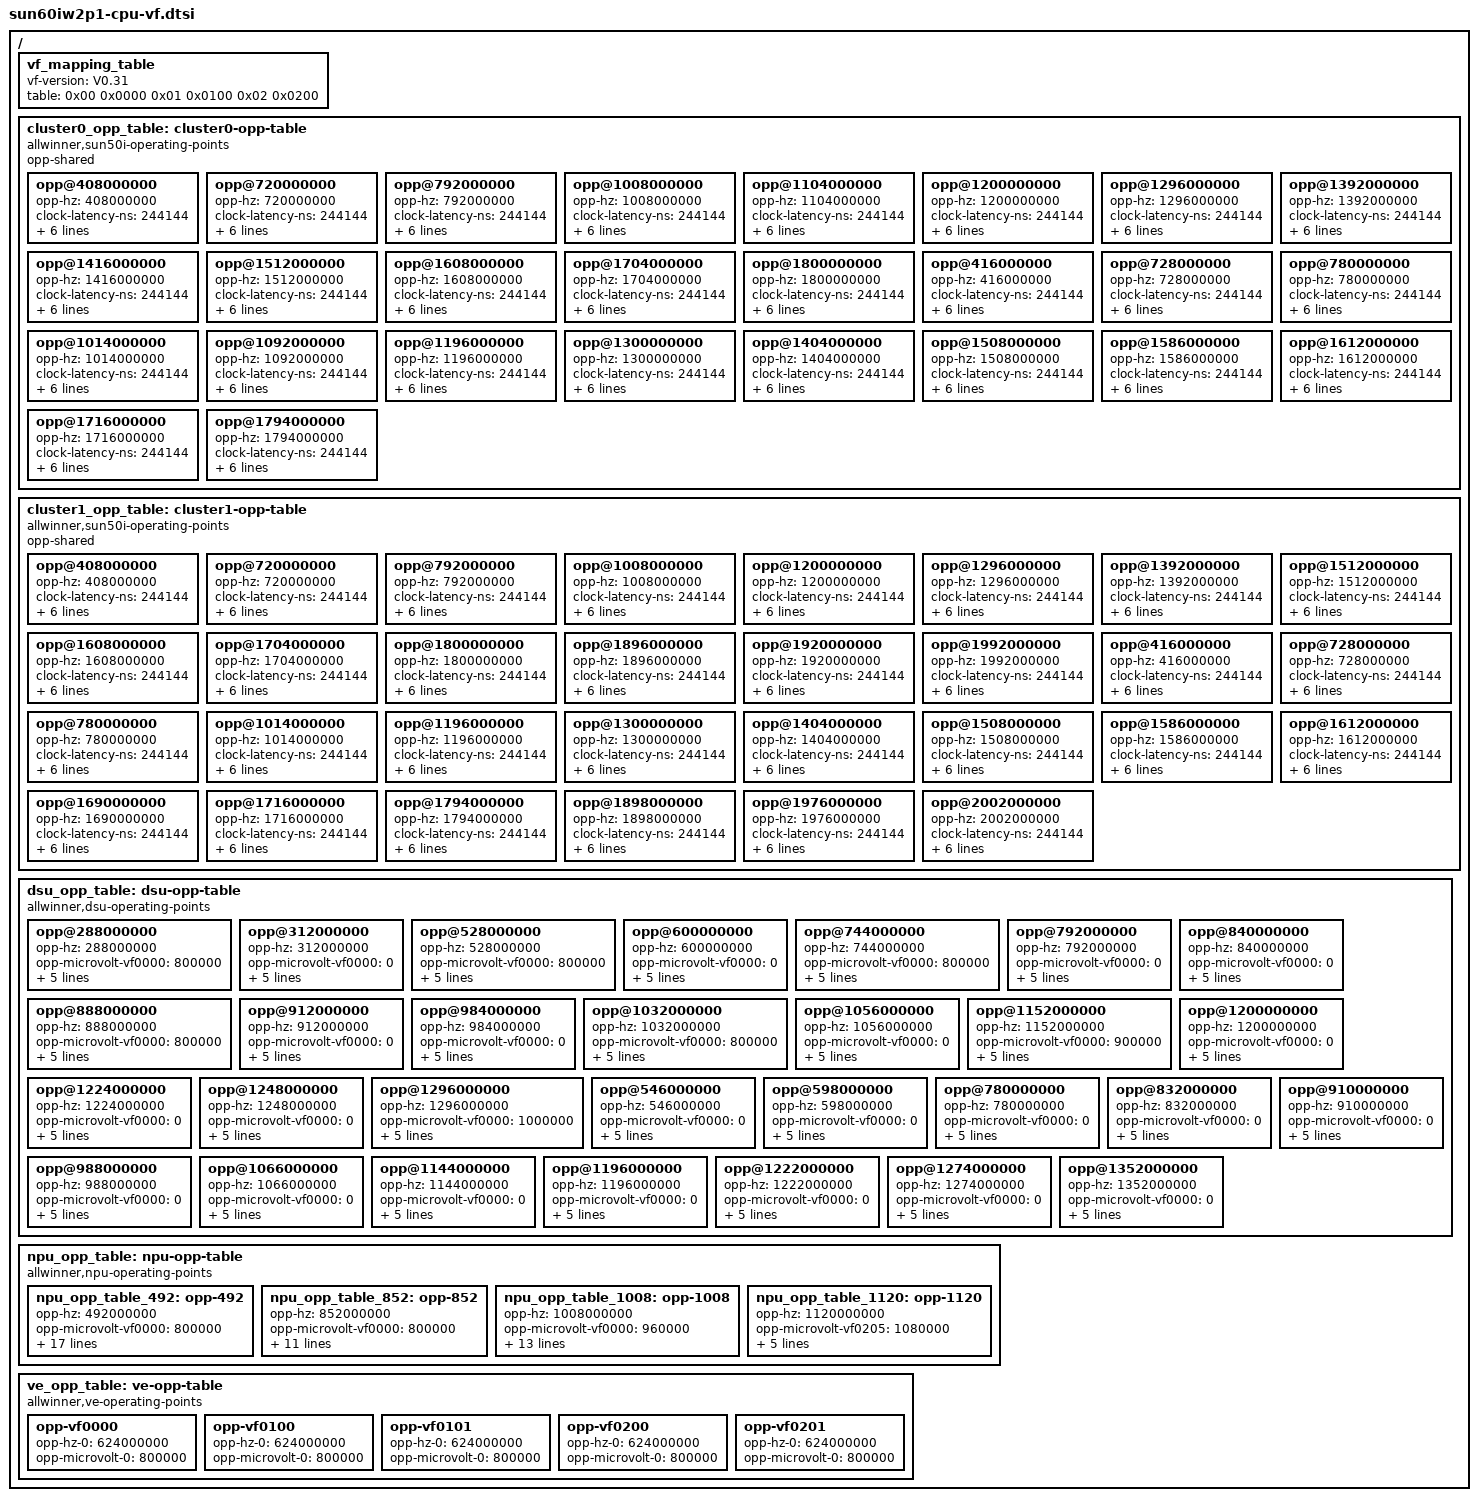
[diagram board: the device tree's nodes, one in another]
/* SPDX-License-Identifier: GPL-2.0-or-later */
/{
	vf_mapping_table: vf_mapping_table {
		vf-version = "V0.31";
		table = <
			0x00 0x0000
			0x01 0x0100
			0x02 0x0200
			>;
	};

	cluster0_opp_table: cluster0-opp-table {
		compatible = "allwinner,sun50i-operating-points";
		opp-shared;

		opp@408000000 {
			opp-hz = /bits/ 64 <408000000>;
			clock-latency-ns = <244144>; /* 8 32k periods */
			opp-microvolt-vf0000 = <800000>;
			opp-microvolt-vf0100 = <800000>;
			opp-microvolt-vf0200 = <800000>;
			opp-microvolt-26m-vf0000 = <0>;
			opp-microvolt-26m-vf0100 = <0>;
			opp-microvolt-26m-vf0200 = <0>;
		};

		opp@720000000 {
			opp-hz = /bits/ 64 <720000000>;
			clock-latency-ns = <244144>; /* 8 32k periods */
			opp-microvolt-vf0000 = <800000>;
			opp-microvolt-vf0100 = <0>;
			opp-microvolt-vf0200 = <0>;
			opp-microvolt-26m-vf0000 = <0>;
			opp-microvolt-26m-vf0100 = <0>;
			opp-microvolt-26m-vf0200 = <0>;
		};

		opp@792000000 {
			opp-hz = /bits/ 64 <792000000>;
			clock-latency-ns = <244144>; /* 8 32k periods */
			opp-microvolt-vf0000 = <0>;
			opp-microvolt-vf0100 = <800000>;
			opp-microvolt-vf0200 = <800000>;
			opp-microvolt-26m-vf0000 = <0>;
			opp-microvolt-26m-vf0100 = <0>;
			opp-microvolt-26m-vf0200 = <0>;
		};

		opp@1008000000 {
			opp-hz = /bits/ 64 <1008000000>;
			clock-latency-ns = <244144>; /* 8 32k periods */
			opp-microvolt-vf0000 = <800000>;
			opp-microvolt-vf0100 = <800000>;
			opp-microvolt-vf0200 = <800000>;
			opp-microvolt-26m-vf0000 = <0>;
			opp-microvolt-26m-vf0100 = <0>;
			opp-microvolt-26m-vf0200 = <0>;
		};

		opp@1104000000 {
			opp-hz = /bits/ 64 <1104000000>;
			clock-latency-ns = <244144>; /* 8 32k periods */
			opp-microvolt-vf0000 = <0>;
			opp-microvolt-vf0100 = <800000>;
			opp-microvolt-vf0200 = <0>;
			opp-microvolt-26m-vf0000 = <0>;
			opp-microvolt-26m-vf0100 = <0>;
			opp-microvolt-26m-vf0200 = <0>;
		};


		opp@1200000000 {
			opp-hz = /bits/ 64 <1200000000>;
			clock-latency-ns = <244144>; /* 8 32k periods */
			opp-microvolt-vf0000 = <800000>;
			opp-microvolt-vf0100 = <850000>;
			opp-microvolt-vf0200 = <800000>;
			opp-microvolt-26m-vf0000 = <0>;
			opp-microvolt-26m-vf0100 = <0>;
			opp-microvolt-26m-vf0200 = <0>;
		};

		opp@1296000000 {
			opp-hz = /bits/ 64 <1296000000>;
			clock-latency-ns = <244144>; /* 8 32k periods */
			opp-microvolt-vf0000 = <0>;
			opp-microvolt-vf0100 = <900000>;
			opp-microvolt-vf0200 = <800000>;
			opp-microvolt-26m-vf0000 = <0>;
			opp-microvolt-26m-vf0100 = <0>;
			opp-microvolt-26m-vf0200 = <0>;
		};


		opp@1392000000 {
			opp-hz = /bits/ 64 <1392000000>;
			clock-latency-ns = <244144>; /* 8 32k periods */
			opp-microvolt-vf0000 = <0>;
			opp-microvolt-vf0100 = <950000>;
			opp-microvolt-vf0200 = <850000>;
			opp-microvolt-26m-vf0000 = <0>;
			opp-microvolt-26m-vf0100 = <0>;
			opp-microvolt-26m-vf0200 = <0>;
		};

		opp@1416000000 {
			opp-hz = /bits/ 64 <1416000000>;
			clock-latency-ns = <244144>; /* 8 32k periods */
			opp-microvolt-vf0000 = <800000>;
			opp-microvolt-vf0100 = <0>;
			opp-microvolt-vf0200 = <0>;
			opp-microvolt-26m-vf0000 = <0>;
			opp-microvolt-26m-vf0100 = <0>;
			opp-microvolt-26m-vf0200 = <0>;
		};

		opp@1512000000 {
			opp-hz = /bits/ 64 <1512000000>;
			clock-latency-ns = <244144>; /* 8 32k periods */
			opp-microvolt-vf0000 = <0>;
			opp-microvolt-vf0100 = <1000000>;
			opp-microvolt-vf0200 = <900000>;
			opp-microvolt-26m-vf0000 = <0>;
			opp-microvolt-26m-vf0100 = <0>;
			opp-microvolt-26m-vf0200 = <0>;
		};

		opp@1608000000 {
			opp-hz = /bits/ 64 <1608000000>;
			clock-latency-ns = <244144>; /* 8 32k periods */
			opp-microvolt-vf0000 = <900000>;
			opp-microvolt-vf0100 = <1050000>;
			opp-microvolt-vf0200 = <950000>;
			opp-microvolt-26m-vf0000 = <0>;
			opp-microvolt-26m-vf0100 = <0>;
			opp-microvolt-26m-vf0200 = <0>;
		};

		opp@1704000000 {
			opp-hz = /bits/ 64 <1704000000>;
			clock-latency-ns = <244144>; /* 8 32k periods */
			opp-microvolt-vf0000 = <0>;
			opp-microvolt-vf0100 = <0>;
			opp-microvolt-vf0200 = <1000000>;
			opp-microvolt-26m-vf0000 = <0>;
			opp-microvolt-26m-vf0100 = <0>;
			opp-microvolt-26m-vf0200 = <0>;
		};

		opp@1800000000 {
			opp-hz = /bits/ 64 <1800000000>;
			clock-latency-ns = <244144>; /* 8 32k periods */
			opp-microvolt-vf0000 = <1000000>;
			opp-microvolt-vf0100 = <0>;
			opp-microvolt-vf0200 = <1050000>;
			opp-microvolt-26m-vf0000 = <0>;
			opp-microvolt-26m-vf0100 = <0>;
			opp-microvolt-26m-vf0200 = <0>;
		};

		/* support 26m clock source */
		opp@416000000 {
			opp-hz = /bits/ 64 <416000000>;
			clock-latency-ns = <244144>;
			opp-microvolt-vf0000 = <0>;
			opp-microvolt-vf0100 = <0>;
			opp-microvolt-vf0200 = <0>;
			opp-microvolt-26m-vf0000 = <800000>;
			opp-microvolt-26m-vf0100 = <800000>;
			opp-microvolt-26m-vf0200 = <800000>;
		};

		opp@728000000 {
			opp-hz = /bits/ 64 <728000000>;
			clock-latency-ns = <244144>;
			opp-microvolt-vf0000 = <0>;
			opp-microvolt-vf0100 = <0>;
			opp-microvolt-vf0200 = <0>;
			opp-microvolt-26m-vf0000 = <800000>;
			opp-microvolt-26m-vf0100 = <0>;
			opp-microvolt-26m-vf0200 = <0>;
		};

		opp@780000000 {
			opp-hz = /bits/ 64 <780000000>;
			clock-latency-ns = <244144>;
			opp-microvolt-vf0000 = <0>;
			opp-microvolt-vf0100 = <0>;
			opp-microvolt-vf0200 = <0>;
			opp-microvolt-26m-vf0000 = <0>;
			opp-microvolt-26m-vf0100 = <800000>;
			opp-microvolt-26m-vf0200 = <800000>;
		};

		opp@1014000000 {
			opp-hz = /bits/ 64 <1014000000>;
			clock-latency-ns = <244144>;
			opp-microvolt-vf0000 = <0>;
			opp-microvolt-vf0100 = <0>;
			opp-microvolt-vf0200 = <0>;
			opp-microvolt-26m-vf0000 = <800000>;
			opp-microvolt-26m-vf0100 = <800000>;
			opp-microvolt-26m-vf0200 = <800000>;
		};

		opp@1092000000 {
			opp-hz = /bits/ 64 <1092000000>;
			clock-latency-ns = <244144>;
			opp-microvolt-vf0000 = <0>;
			opp-microvolt-vf0100 = <0>;
			opp-microvolt-vf0200 = <0>;
			opp-microvolt-26m-vf0000 = <0>;
			opp-microvolt-26m-vf0100 = <800000>;
			opp-microvolt-26m-vf0200 = <0>;
		};

		opp@1196000000 {
			opp-hz = /bits/ 64 <1196000000>;
			clock-latency-ns = <244144>;
			opp-microvolt-vf0000 = <0>;
			opp-microvolt-vf0100 = <0>;
			opp-microvolt-vf0200 = <0>;
			opp-microvolt-26m-vf0000 = <800000>;
			opp-microvolt-26m-vf0100 = <850000>;
			opp-microvolt-26m-vf0200 = <800000>;
		};

		opp@1300000000 {
			opp-hz = /bits/ 64 <1300000000>;
			clock-latency-ns = <244144>;
			opp-microvolt-vf0000 = <0>;
			opp-microvolt-vf0100 = <0>;
			opp-microvolt-vf0200 = <0>;
			opp-microvolt-26m-vf0000 = <0>;
			opp-microvolt-26m-vf0100 = <900000>;
			opp-microvolt-26m-vf0200 = <800000>;
		};

		opp@1404000000 {
			opp-hz = /bits/ 64 <1404000000>;
			clock-latency-ns = <244144>;
			opp-microvolt-vf0000 = <0>;
			opp-microvolt-vf0100 = <0>;
			opp-microvolt-vf0200 = <0>;
			opp-microvolt-26m-vf0000 = <800000>;
			opp-microvolt-26m-vf0100 = <950000>;
			opp-microvolt-26m-vf0200 = <850000>;
		};

		opp@1508000000 {
			opp-hz = /bits/ 64 <1508000000>;
			clock-latency-ns = <244144>;
			opp-microvolt-vf0000 = <0>;
			opp-microvolt-vf0100 = <0>;
			opp-microvolt-vf0200 = <0>;
			opp-microvolt-26m-vf0000 = <0>;
			opp-microvolt-26m-vf0100 = <1000000>;
			opp-microvolt-26m-vf0200 = <900000>;
		};

		opp@1586000000 {
			opp-hz = /bits/ 64 <1586000000>;
			clock-latency-ns = <244144>;
			opp-microvolt-vf0000 = <0>;
			opp-microvolt-vf0100 = <0>;
			opp-microvolt-vf0200 = <0>;
			opp-microvolt-26m-vf0000 = <900000>;
			opp-microvolt-26m-vf0100 = <0>;
			opp-microvolt-26m-vf0200 = <0>;
		};

		opp@1612000000 {
			opp-hz = /bits/ 64 <1612000000>;
			clock-latency-ns = <244144>;
			opp-microvolt-vf0000 = <0>;
			opp-microvolt-vf0100 = <0>;
			opp-microvolt-vf0200 = <0>;
			opp-microvolt-26m-vf0000 = <0>;
			opp-microvolt-26m-vf0100 = <1050000>;
			opp-microvolt-26m-vf0200 = <950000>;
		};

		opp@1716000000 {
			opp-hz = /bits/ 64 <1716000000>;
			clock-latency-ns = <244144>;
			opp-microvolt-vf0000 = <0>;
			opp-microvolt-vf0100 = <0>;
			opp-microvolt-vf0200 = <0>;
			opp-microvolt-26m-vf0000 = <0>;
			opp-microvolt-26m-vf0100 = <0>;
			opp-microvolt-26m-vf0200 = <1000000>;
		};

		opp@1794000000 {
			opp-hz = /bits/ 64 <1794000000>;
			clock-latency-ns = <244144>;
			opp-microvolt-vf0000 = <0>;
			opp-microvolt-vf0100 = <0>;
			opp-microvolt-vf0200 = <0>;
			opp-microvolt-26m-vf0000 = <1000000>;
			opp-microvolt-26m-vf0100 = <0>;
			opp-microvolt-26m-vf0200 = <1050000>;
		};
	};

	cluster1_opp_table: cluster1-opp-table {
		compatible = "allwinner,sun50i-operating-points";
		opp-shared;

		opp@408000000 {
			opp-hz = /bits/ 64 <408000000>;
			clock-latency-ns = <244144>; /* 8 32k periods */
			opp-microvolt-vf0000 = <800000>;
			opp-microvolt-vf0100 = <800000>;
			opp-microvolt-vf0200 = <800000>;
			opp-microvolt-26m-vf0000 = <0>;
			opp-microvolt-26m-vf0100 = <0>;
			opp-microvolt-26m-vf0200 = <0>;
		};

		opp@720000000 {
			opp-hz = /bits/ 64 <720000000>;
			clock-latency-ns = <244144>; /* 8 32k periods */
			opp-microvolt-vf0000 = <800000>;
			opp-microvolt-vf0100 = <0>;
			opp-microvolt-vf0200 = <0>;
			opp-microvolt-26m-vf0000 = <0>;
			opp-microvolt-26m-vf0100 = <0>;
			opp-microvolt-26m-vf0200 = <0>;
		};

		opp@792000000 {
			opp-hz = /bits/ 64 <792000000>;
			clock-latency-ns = <244144>; /* 8 32k periods */
			opp-microvolt-vf0000 = <0>;
			opp-microvolt-vf0100 = <800000>;
			opp-microvolt-vf0200 = <800000>;
			opp-microvolt-26m-vf0000 = <0>;
			opp-microvolt-26m-vf0100 = <0>;
			opp-microvolt-26m-vf0200 = <0>;
		};


		opp@1008000000 {
			opp-hz = /bits/ 64 <1008000000>;
			clock-latency-ns = <244144>; /* 8 32k periods */
			opp-microvolt-vf0000 = <800000>;
			opp-microvolt-vf0100 = <800000>;
			opp-microvolt-vf0200 = <800000>;
			opp-microvolt-26m-vf0000 = <0>;
			opp-microvolt-26m-vf0100 = <0>;
			opp-microvolt-26m-vf0200 = <0>;
		};

		opp@1200000000 {
			opp-hz = /bits/ 64 <1200000000>;
			clock-latency-ns = <244144>; /* 8 32k periods */
			opp-microvolt-vf0000 = <800000>;
			opp-microvolt-vf0100 = <800000>;
			opp-microvolt-vf0200 = <800000>;
			opp-microvolt-26m-vf0000 = <0>;
			opp-microvolt-26m-vf0100 = <0>;
			opp-microvolt-26m-vf0200 = <0>;
		};

		opp@1296000000 {
			opp-hz = /bits/ 64 <1296000000>;
			clock-latency-ns = <244144>; /* 8 32k periods */
			opp-microvolt-vf0000 = <0>;
			opp-microvolt-vf0100 = <800000>;
			opp-microvolt-vf0200 = <0>;
			opp-microvolt-26m-vf0000 = <0>;
			opp-microvolt-26m-vf0100 = <0>;
			opp-microvolt-26m-vf0200 = <0>;
		};

		opp@1392000000 {
			opp-hz = /bits/ 64 <1392000000>;
			clock-latency-ns = <244144>; /* 8 32k periods */
			opp-microvolt-vf0000 = <800000>;
			opp-microvolt-vf0100 = <850000>;
			opp-microvolt-vf0200 = <800000>;
			opp-microvolt-26m-vf0000 = <0>;
			opp-microvolt-26m-vf0100 = <0>;
			opp-microvolt-26m-vf0200 = <0>;
		};

		opp@1512000000 {
			opp-hz = /bits/ 64 <1512000000>;
			clock-latency-ns = <244144>; /* 8 32k periods */
			opp-microvolt-vf0000 = <800000>;
			opp-microvolt-vf0100 = <900000>;
			opp-microvolt-vf0200 = <800000>;
			opp-microvolt-26m-vf0000 = <0>;
			opp-microvolt-26m-vf0100 = <0>;
			opp-microvolt-26m-vf0200 = <0>;
		};

		opp@1608000000 {
			opp-hz = /bits/ 64 <1608000000>;
			clock-latency-ns = <244144>; /* 8 32k periods */
			opp-microvolt-vf0000 = <850000>;
			opp-microvolt-vf0100 = <950000>;
			opp-microvolt-vf0200 = <850000>;
			opp-microvolt-26m-vf0000 = <0>;
			opp-microvolt-26m-vf0100 = <0>;
			opp-microvolt-26m-vf0200 = <0>;
		};

		opp@1704000000 {
			opp-hz = /bits/ 64 <1704000000>;
			clock-latency-ns = <244144>; /* 8 32k periods */
			opp-microvolt-vf0000 = <900000>;
			opp-microvolt-vf0100 = <1000000>;
			opp-microvolt-vf0200 = <900000>;
			opp-microvolt-26m-vf0000 = <0>;
			opp-microvolt-26m-vf0100 = <0>;
			opp-microvolt-26m-vf0200 = <0>;
		};

		opp@1800000000 {
			opp-hz = /bits/ 64 <1800000000>;
			clock-latency-ns = <244144>; /* 8 32k periods */
			opp-microvolt-vf0000 = <950000>;
			opp-microvolt-vf0100 = <1050000>;
			opp-microvolt-vf0200 = <950000>;
			opp-microvolt-26m-vf0000 = <0>;
			opp-microvolt-26m-vf0100 = <0>;
			opp-microvolt-26m-vf0200 = <0>;
		};

		opp@1896000000 {
			opp-hz = /bits/ 64 <1896000000>;
			clock-latency-ns = <244144>; /* 8 32k periods */
			opp-microvolt-vf0000 = <0>;
			opp-microvolt-vf0100 = <0>;
			opp-microvolt-vf0200 = <1000000>;
			opp-microvolt-26m-vf0000 = <0>;
			opp-microvolt-26m-vf0100 = <0>;
			opp-microvolt-26m-vf0200 = <0>;
		};


		opp@1920000000 {
			opp-hz = /bits/ 64 <1920000000>;
			clock-latency-ns = <244144>; /* 8 32k periods */
			opp-microvolt-vf0000 = <1000000>;
			opp-microvolt-vf0100 = <0>;
			opp-microvolt-vf0200 = <0>;
			opp-microvolt-26m-vf0000 = <0>;
			opp-microvolt-26m-vf0100 = <0>;
			opp-microvolt-26m-vf0200 = <0>;
		};

		opp@1992000000 {
			opp-hz = /bits/ 64 <1992000000>;
			clock-latency-ns = <244144>; /* 8 32k periods */
			opp-microvolt-vf0000 = <1050000>;
			opp-microvolt-vf0100 = <0>;
			opp-microvolt-vf0200 = <1050000>;
			opp-microvolt-26m-vf0000 = <0>;
			opp-microvolt-26m-vf0100 = <0>;
			opp-microvolt-26m-vf0200 = <0>;
		};


		/* support 26m clock source */
		opp@416000000 {
			opp-hz = /bits/ 64 <416000000>;
			clock-latency-ns = <244144>;
			opp-microvolt-vf0000 = <0>;
			opp-microvolt-vf0100 = <0>;
			opp-microvolt-vf0200 = <0>;
			opp-microvolt-26m-vf0000 = <800000>;
			opp-microvolt-26m-vf0100 = <800000>;
			opp-microvolt-26m-vf0200 = <800000>;
		};

		opp@728000000 {
			opp-hz = /bits/ 64 <728000000>;
			clock-latency-ns = <244144>;
			opp-microvolt-vf0000 = <0>;
			opp-microvolt-vf0100 = <0>;
			opp-microvolt-vf0200 = <0>;
			opp-microvolt-26m-vf0000 = <800000>;
			opp-microvolt-26m-vf0100 = <0>;
			opp-microvolt-26m-vf0200 = <0>;
		};

		opp@780000000 {
			opp-hz = /bits/ 64 <780000000>;
			clock-latency-ns = <244144>;
			opp-microvolt-vf0000 = <0>;
			opp-microvolt-vf0100 = <0>;
			opp-microvolt-vf0200 = <0>;
			opp-microvolt-26m-vf0000 = <0>;
			opp-microvolt-26m-vf0100 = <800000>;
			opp-microvolt-26m-vf0200 = <800000>;
		};

		opp@1014000000 {
			opp-hz = /bits/ 64 <1014000000>;
			clock-latency-ns = <244144>;
			opp-microvolt-vf0000 = <0>;
			opp-microvolt-vf0100 = <0>;
			opp-microvolt-vf0200 = <0>;
			opp-microvolt-26m-vf0000 = <800000>;
			opp-microvolt-26m-vf0100 = <800000>;
			opp-microvolt-26m-vf0200 = <800000>;
		};

		opp@1196000000 {
			opp-hz = /bits/ 64 <1196000000>;
			clock-latency-ns = <244144>;
			opp-microvolt-vf0000 = <0>;
			opp-microvolt-vf0100 = <0>;
			opp-microvolt-vf0200 = <0>;
			opp-microvolt-26m-vf0000 = <800000>;
			opp-microvolt-26m-vf0100 = <800000>;
			opp-microvolt-26m-vf0200 = <800000>;
		};

		opp@1300000000 {
			opp-hz = /bits/ 64 <1300000000>;
			clock-latency-ns = <244144>;
			opp-microvolt-vf0000 = <0>;
			opp-microvolt-vf0100 = <0>;
			opp-microvolt-vf0200 = <0>;
			opp-microvolt-26m-vf0000 = <0>;
			opp-microvolt-26m-vf0100 = <800000>;
			opp-microvolt-26m-vf0200 = <0>;
		};

		opp@1404000000 {
			opp-hz = /bits/ 64 <1404000000>;
			clock-latency-ns = <244144>;
			opp-microvolt-vf0000 = <0>;
			opp-microvolt-vf0100 = <0>;
			opp-microvolt-vf0200 = <0>;
			opp-microvolt-26m-vf0000 = <800000>;
			opp-microvolt-26m-vf0100 = <850000>;
			opp-microvolt-26m-vf0200 = <800000>;
		};

		opp@1508000000 {
			opp-hz = /bits/ 64 <1508000000>;
			clock-latency-ns = <244144>;
			opp-microvolt-vf0000 = <0>;
			opp-microvolt-vf0100 = <0>;
			opp-microvolt-vf0200 = <0>;
			opp-microvolt-26m-vf0000 = <800000>;
			opp-microvolt-26m-vf0100 = <900000>;
			opp-microvolt-26m-vf0200 = <800000>;
		};

		opp@1586000000 {
			opp-hz = /bits/ 64 <1586000000>;
			clock-latency-ns = <244144>;
			opp-microvolt-vf0000 = <0>;
			opp-microvolt-vf0100 = <0>;
			opp-microvolt-vf0200 = <0>;
			opp-microvolt-26m-vf0000 = <850000>;
			opp-microvolt-26m-vf0100 = <0>;
			opp-microvolt-26m-vf0200 = <0>;
		};

		opp@1612000000 {
			opp-hz = /bits/ 64 <1612000000>;
			clock-latency-ns = <244144>;
			opp-microvolt-vf0000 = <0>;
			opp-microvolt-vf0100 = <0>;
			opp-microvolt-vf0200 = <0>;
			opp-microvolt-26m-vf0000 = <0>;
			opp-microvolt-26m-vf0100 = <950000>;
			opp-microvolt-26m-vf0200 = <850000>;
		};

		opp@1690000000 {
			opp-hz = /bits/ 64 <1690000000>;
			clock-latency-ns = <244144>;
			opp-microvolt-vf0000 = <0>;
			opp-microvolt-vf0100 = <0>;
			opp-microvolt-vf0200 = <0>;
			opp-microvolt-26m-vf0000 = <900000>;
			opp-microvolt-26m-vf0100 = <0>;
			opp-microvolt-26m-vf0200 = <0>;
		};

		opp@1716000000 {
			opp-hz = /bits/ 64 <1716000000>;
			clock-latency-ns = <244144>;
			opp-microvolt-vf0000 = <0>;
			opp-microvolt-vf0100 = <0>;
			opp-microvolt-vf0200 = <0>;
			opp-microvolt-26m-vf0000 = <0>;
			opp-microvolt-26m-vf0100 = <1000000>;
			opp-microvolt-26m-vf0200 = <900000>;
		};

		opp@1794000000 {
			opp-hz = /bits/ 64 <1794000000>;
			clock-latency-ns = <244144>;
			opp-microvolt-vf0000 = <0>;
			opp-microvolt-vf0100 = <0>;
			opp-microvolt-vf0200 = <0>;
			opp-microvolt-26m-vf0000 = <950000>;
			opp-microvolt-26m-vf0100 = <1050000>;
			opp-microvolt-26m-vf0200 = <950000>;
		};

		opp@1898000000 {
			opp-hz = /bits/ 64 <1898000000>;
			clock-latency-ns = <244144>;
			opp-microvolt-vf0000 = <0>;
			opp-microvolt-vf0100 = <0>;
			opp-microvolt-vf0200 = <0>;
			opp-microvolt-26m-vf0000 = <1000000>;
			opp-microvolt-26m-vf0100 = <0>;
			opp-microvolt-26m-vf0200 = <1000000>;
		};

		opp@1976000000 {
			opp-hz = /bits/ 64 <1976000000>;
			clock-latency-ns = <244144>;
			opp-microvolt-vf0000 = <0>;
			opp-microvolt-vf0100 = <0>;
			opp-microvolt-vf0200 = <0>;
			opp-microvolt-26m-vf0000 = <1050000>;
			opp-microvolt-26m-vf0100 = <0>;
			opp-microvolt-26m-vf0200 = <0>;
		};

		opp@2002000000 {
			opp-hz = /bits/ 64 <2002000000>;
			clock-latency-ns = <244144>;
			opp-microvolt-vf0000 = <0>;
			opp-microvolt-vf0100 = <0>;
			opp-microvolt-vf0200 = <0>;
			opp-microvolt-26m-vf0000 = <0>;
			opp-microvolt-26m-vf0100 = <0>;
			opp-microvolt-26m-vf0200 = <1050000>;
		};
	};

	dsu_opp_table: dsu-opp-table {
		compatible = "allwinner,dsu-operating-points";

		opp@288000000 {
			opp-hz = /bits/ 64 <288000000>;
			opp-microvolt-vf0000 = <800000>;
			opp-microvolt-vf0100 = <0>;
			opp-microvolt-vf0200 = <0>;
			opp-microvolt-26m-vf0000 = <0>;
			opp-microvolt-26m-vf0100 = <0>;
			opp-microvolt-26m-vf0200 = <0>;
		};

		/* this freq support in 24m and 26m */
		opp@312000000 {
			opp-hz = /bits/ 64 <312000000>;
			opp-microvolt-vf0000 = <0>;
			opp-microvolt-vf0100 = <800000>;
			opp-microvolt-vf0200 = <800000>;
			opp-microvolt-26m-vf0000 = <800000>;
			opp-microvolt-26m-vf0100 = <800000>;
			opp-microvolt-26m-vf0200 = <800000>;
		};

		opp@528000000 {
			opp-hz = /bits/ 64 <528000000>;
			opp-microvolt-vf0000 = <800000>;
			opp-microvolt-vf0100 = <0>;
			opp-microvolt-vf0200 = <0>;
			opp-microvolt-26m-vf0000 = <0>;
			opp-microvolt-26m-vf0100 = <0>;
			opp-microvolt-26m-vf0200 = <0>;
		};

		opp@600000000 {
			opp-hz = /bits/ 64 <600000000>;
			opp-microvolt-vf0000 = <0>;
			opp-microvolt-vf0100 = <800000>;
			opp-microvolt-vf0200 = <800000>;
			opp-microvolt-26m-vf0000 = <0>;
			opp-microvolt-26m-vf0100 = <0>;
			opp-microvolt-26m-vf0200 = <0>;
		};

		opp@744000000 {
			opp-hz = /bits/ 64 <744000000>;
			opp-microvolt-vf0000 = <800000>;
			opp-microvolt-vf0100 = <0>;
			opp-microvolt-vf0200 = <0>;
			opp-microvolt-26m-vf0000 = <0>;
			opp-microvolt-26m-vf0100 = <0>;
			opp-microvolt-26m-vf0200 = <0>;
		};

		opp@792000000 {
			opp-hz = /bits/ 64 <792000000>;
			opp-microvolt-vf0000 = <0>;
			opp-microvolt-vf0100 = <800000>;
			opp-microvolt-vf0200 = <800000>;
			opp-microvolt-26m-vf0000 = <0>;
			opp-microvolt-26m-vf0100 = <0>;
			opp-microvolt-26m-vf0200 = <0>;
		};

		opp@840000000 {
			opp-hz = /bits/ 64 <840000000>;
			opp-microvolt-vf0000 = <0>;
			opp-microvolt-vf0100 = <800000>;
			opp-microvolt-vf0200 = <0>;
			opp-microvolt-26m-vf0000 = <0>;
			opp-microvolt-26m-vf0100 = <0>;
			opp-microvolt-26m-vf0200 = <0>;
		};

		opp@888000000 {
			opp-hz = /bits/ 64 <888000000>;
			opp-microvolt-vf0000 = <800000>;
			opp-microvolt-vf0100 = <0>;
			opp-microvolt-vf0200 = <0>;
			opp-microvolt-26m-vf0000 = <0>;
			opp-microvolt-26m-vf0100 = <0>;
			opp-microvolt-26m-vf0200 = <0>;
		};

		opp@912000000 {
			opp-hz = /bits/ 64 <912000000>;
			opp-microvolt-vf0000 = <0>;
			opp-microvolt-vf0100 = <850000>;
			opp-microvolt-vf0200 = <800000>;
			opp-microvolt-26m-vf0000 = <0>;
			opp-microvolt-26m-vf0100 = <0>;
			opp-microvolt-26m-vf0200 = <0>;
		};

		opp@984000000 {
			opp-hz = /bits/ 64 <984000000>;
			opp-microvolt-vf0000 = <0>;
			opp-microvolt-vf0100 = <900000>;
			opp-microvolt-vf0200 = <800000>;
			opp-microvolt-26m-vf0000 = <0>;
			opp-microvolt-26m-vf0100 = <0>;
			opp-microvolt-26m-vf0200 = <0>;
		};

		opp@1032000000 {
			opp-hz = /bits/ 64 <1032000000>;
			opp-microvolt-vf0000 = <800000>;
			opp-microvolt-vf0100 = <0>;
			opp-microvolt-vf0200 = <0>;
			opp-microvolt-26m-vf0000 = <0>;
			opp-microvolt-26m-vf0100 = <0>;
			opp-microvolt-26m-vf0200 = <0>;
		};

		opp@1056000000 {
			opp-hz = /bits/ 64 <1056000000>;
			opp-microvolt-vf0000 = <0>;
			opp-microvolt-vf0100 = <950000>;
			opp-microvolt-vf0200 = <850000>;
			opp-microvolt-26m-vf0000 = <0>;
			opp-microvolt-26m-vf0100 = <0>;
			opp-microvolt-26m-vf0200 = <0>;
		};

		opp@1152000000 {
			opp-hz = /bits/ 64 <1152000000>;
			opp-microvolt-vf0000 = <900000>;
			opp-microvolt-vf0100 = <1000000>;
			opp-microvolt-vf0200 = <900000>;
			opp-microvolt-26m-vf0000 = <0>;
			opp-microvolt-26m-vf0100 = <0>;
			opp-microvolt-26m-vf0200 = <0>;
		};

		opp@1200000000 {
			opp-hz = /bits/ 64 <1200000000>;
			opp-microvolt-vf0000 = <0>;
			opp-microvolt-vf0100 = <1050000>;
			opp-microvolt-vf0200 = <950000>;
			opp-microvolt-26m-vf0000 = <0>;
			opp-microvolt-26m-vf0100 = <0>;
			opp-microvolt-26m-vf0200 = <0>;
		};

		opp@1224000000 {
			opp-hz = /bits/ 64 <1224000000>;
			opp-microvolt-vf0000 = <0>;
			opp-microvolt-vf0100 = <0>;
			opp-microvolt-vf0200 = <1000000>;
			opp-microvolt-26m-vf0000 = <0>;
			opp-microvolt-26m-vf0100 = <0>;
			opp-microvolt-26m-vf0200 = <0>;
		};

		opp@1248000000 {
			opp-hz = /bits/ 64 <1248000000>;
			opp-microvolt-vf0000 = <0>;
			opp-microvolt-vf0100 = <0>;
			opp-microvolt-vf0200 = <1050000>;
			opp-microvolt-26m-vf0000 = <0>;
			opp-microvolt-26m-vf0100 = <0>;
			opp-microvolt-26m-vf0200 = <1000000>;
		};

		opp@1296000000 {
			opp-hz = /bits/ 64 <1296000000>;
			opp-microvolt-vf0000 = <1000000>;
			opp-microvolt-vf0100 = <0>;
			opp-microvolt-vf0200 = <0>;
			opp-microvolt-26m-vf0000 = <0>;
			opp-microvolt-26m-vf0100 = <0>;
			opp-microvolt-26m-vf0200 = <0>;
		};

		/* support 26m clock source */
		/* Support 312m and 1248m in 26m platform, Describe it for the 24m platform above */
		opp@546000000 {
			opp-hz = /bits/ 64 <546000000>;
			opp-microvolt-vf0000 = <0>;
			opp-microvolt-vf0100 = <0>;
			opp-microvolt-vf0200 = <0>;
			opp-microvolt-26m-vf0000 = <800000>;
			opp-microvolt-26m-vf0100 = <0>;
			opp-microvolt-26m-vf0200 = <0>;
		};

		opp@598000000 {
			opp-hz = /bits/ 64 <598000000>;
			opp-microvolt-vf0000 = <0>;
			opp-microvolt-vf0100 = <0>;
			opp-microvolt-vf0200 = <0>;
			opp-microvolt-26m-vf0000 = <0>;
			opp-microvolt-26m-vf0100 = <800000>;
			opp-microvolt-26m-vf0200 = <800000>;
		};

		opp@780000000 {
			opp-hz = /bits/ 64 <780000000>;
			opp-microvolt-vf0000 = <0>;
			opp-microvolt-vf0100 = <0>;
			opp-microvolt-vf0200 = <0>;
			opp-microvolt-26m-vf0000 = <800000>;
			opp-microvolt-26m-vf0100 = <800000>;
			opp-microvolt-26m-vf0200 = <800000>;
		};

		opp@832000000 {
			opp-hz = /bits/ 64 <832000000>;
			opp-microvolt-vf0000 = <0>;
			opp-microvolt-vf0100 = <0>;
			opp-microvolt-vf0200 = <0>;
			opp-microvolt-26m-vf0000 = <0>;
			opp-microvolt-26m-vf0100 = <800000>;
			opp-microvolt-26m-vf0200 = <0>;
		};

		opp@910000000 {
			opp-hz = /bits/ 64 <910000000>;
			opp-microvolt-vf0000 = <0>;
			opp-microvolt-vf0100 = <0>;
			opp-microvolt-vf0200 = <0>;
			opp-microvolt-26m-vf0000 = <800000>;
			opp-microvolt-26m-vf0100 = <850000>;
			opp-microvolt-26m-vf0200 = <800000>;
		};

		opp@988000000 {
			opp-hz = /bits/ 64 <988000000>;
			opp-microvolt-vf0000 = <0>;
			opp-microvolt-vf0100 = <0>;
			opp-microvolt-vf0200 = <0>;
			opp-microvolt-26m-vf0000 = <0>;
			opp-microvolt-26m-vf0100 = <900000>;
			opp-microvolt-26m-vf0200 = <800000>;
		};

		opp@1066000000 {
			opp-hz = /bits/ 64 <1066000000>;
			opp-microvolt-vf0000 = <0>;
			opp-microvolt-vf0100 = <0>;
			opp-microvolt-vf0200 = <0>;
			opp-microvolt-26m-vf0000 = <800000>;
			opp-microvolt-26m-vf0100 = <950000>;
			opp-microvolt-26m-vf0200 = <850000>;
		};

		opp@1144000000 {
			opp-hz = /bits/ 64 <1144000000>;
			opp-microvolt-vf0000 = <0>;
			opp-microvolt-vf0100 = <0>;
			opp-microvolt-vf0200 = <0>;
			opp-microvolt-26m-vf0000 = <0>;
			opp-microvolt-26m-vf0100 = <1000000>;
			opp-microvolt-26m-vf0200 = <900000>;
		};

		opp@1196000000 {
			opp-hz = /bits/ 64 <1196000000>;
			opp-microvolt-vf0000 = <0>;
			opp-microvolt-vf0100 = <0>;
			opp-microvolt-vf0200 = <0>;
			opp-microvolt-26m-vf0000 = <900000>;
			opp-microvolt-26m-vf0100 = <0>;
			opp-microvolt-26m-vf0200 = <0>;
		};

		opp@1222000000 {
			opp-hz = /bits/ 64 <1222000000>;
			opp-microvolt-vf0000 = <0>;
			opp-microvolt-vf0100 = <0>;
			opp-microvolt-vf0200 = <0>;
			opp-microvolt-26m-vf0000 = <0>;
			opp-microvolt-26m-vf0100 = <1050000>;
			opp-microvolt-26m-vf0200 = <950000>;
		};

		opp@1274000000 {
			opp-hz = /bits/ 64 <1274000000>;
			opp-microvolt-vf0000 = <0>;
			opp-microvolt-vf0100 = <0>;
			opp-microvolt-vf0200 = <0>;
			opp-microvolt-26m-vf0000 = <0>;
			opp-microvolt-26m-vf0100 = <0>;
			opp-microvolt-26m-vf0200 = <1050000>;
		};

		opp@1352000000 {
			opp-hz = /bits/ 64 <1352000000>;
			opp-microvolt-vf0000 = <0>;
			opp-microvolt-vf0100 = <0>;
			opp-microvolt-vf0200 = <0>;
			opp-microvolt-26m-vf0000 = <1000000>;
			opp-microvolt-26m-vf0100 = <0>;
			opp-microvolt-26m-vf0200 = <0>;
		};
	};

	npu_opp_table: npu-opp-table {
		compatible = "allwinner,npu-operating-points";

		npu_opp_table_492: opp-492 {
			opp-hz = /bits/ 64 <492000000>;
			opp-microvolt-vf0000 = <800000>;
			opp-microvolt-vf0200 = <800000>;
			opp-microvolt-vf0201 = <800000>;
			opp-microvolt-vf0202 = <800000>;
			opp-microvolt-vf0203 = <800000>;
			opp-microvolt-vf0204 = <800000>;
			opp-microvolt-vf0205 = <800000>;
			opp-microvolt-vf0206 = <800000>;
			opp-microvolt-vf0300 = <800000>;
			opp-microvolt-26m-vf0000 = <800000>;
			opp-microvolt-26m-vf0200 = <800000>;
			opp-microvolt-26m-vf0201 = <800000>;
			opp-microvolt-26m-vf0202 = <800000>;
			opp-microvolt-26m-vf0203 = <800000>;
			opp-microvolt-26m-vf0204 = <800000>;
			opp-microvolt-26m-vf0205 = <800000>;
			opp-microvolt-26m-vf0206 = <800000>;
			opp-microvolt-26m-vf0300 = <800000>;
		};

		npu_opp_table_852: opp-852 {
			opp-hz = /bits/ 64 <852000000>;
			opp-microvolt-vf0000 = <800000>;
			opp-microvolt-vf0200 = <800000>;
			opp-microvolt-vf0201 = <800000>;
			opp-microvolt-vf0202 = <880000>;
			opp-microvolt-vf0203 = <880000>;
			opp-microvolt-vf0204 = <880000>;
			opp-microvolt-26m-vf0000 = <800000>;
			opp-microvolt-26m-vf0200 = <800000>;
			opp-microvolt-26m-vf0201 = <800000>;
			opp-microvolt-26m-vf0202 = <880000>;
			opp-microvolt-26m-vf0203 = <880000>;
			opp-microvolt-26m-vf0204 = <800000>;
		};

		npu_opp_table_1008: opp-1008 {
			opp-hz = /bits/ 64 <1008000000>;
			opp-microvolt-vf0000 = <960000>;
			opp-microvolt-vf0202 = <1030000>;
			opp-microvolt-vf0203 = <1030000>;
			opp-microvolt-vf0204 = <1000000>;
			opp-microvolt-vf0205 = <960000>;
			opp-microvolt-vf0206 = <900000>;
			opp-microvolt-vf0300 = <900000>;
			opp-microvolt-26m-vf0000 = <960000>;
			opp-microvolt-26m-vf0202 = <1030000>;
			opp-microvolt-26m-vf0203 = <1030000>;
			opp-microvolt-26m-vf0204 = <1000000>;
			opp-microvolt-26m-vf0205 = <960000>;
			opp-microvolt-26m-vf0206 = <900000>;
			opp-microvolt-26m-vf0300 = <900000>;
		};

		npu_opp_table_1120: opp-1120 {
			opp-hz = /bits/ 64 <1120000000>;
			opp-microvolt-vf0205 = <1080000>;
			opp-microvolt-vf0206 = <1040000>;
			opp-microvolt-vf0300 = <1040000>;
			opp-microvolt-26m-vf0205 = <1080000>;
			opp-microvolt-26m-vf0206 = <1040000>;
			opp-microvolt-26m-vf0300 = <1040000>;
		};
	};

	ve_opp_table: ve-opp-table {
		compatible = "allwinner,ve-operating-points";

		opp-vf0000 {
			opp-hz-0 = /bits/ 64 <624000000>;
			opp-microvolt-0 = <800000>;
		};
		opp-vf0100 {
			opp-hz-0 = /bits/ 64 <624000000>;
			opp-microvolt-0 = <800000>;
		};
		opp-vf0101 {
			opp-hz-0 = /bits/ 64 <624000000>;
			opp-microvolt-0 = <800000>;
		};
		opp-vf0200 {
			opp-hz-0 = /bits/ 64 <624000000>;
			opp-microvolt-0 = <800000>;
		};
		opp-vf0201 {
			opp-hz-0 = /bits/ 64 <624000000>;
			opp-microvolt-0 = <800000>;
		};
	};
};
